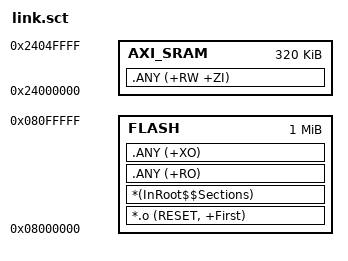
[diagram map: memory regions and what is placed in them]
; *********************************************************************************
; *** Scatter-Loading Description File generated by STM32CubeMX/LinkerGenerator ***
; *********************************************************************************;

ON_CHIP 0x08000000 0x00100000  {  ; load_region size_region
  FLASH 0x08000000 0x00100000  {  ; load address = excetion address
   *.o (RESET, +First)
   *(InRoot$$Sections)
   .ANY (+RO)
   .ANY (+XO)
  }
  AXI_SRAM 0x24000000 0x00050000  {  ; load address = excetion address
   .ANY (+RW +ZI)
  ;  *(.sram1)
  }
;***region***;
  ; ITCM 0x00000000 0x00010000  {  ; load address = excetion address
  ;  *(.itcm)
  ; }
  ; DTCM 0x20000000 0x00020000  {  ; load address = excetion address
  ;  *(.dtcm)
  ; }
  ; AHB_SRAM_D2 0x30000000 0x00008000  {  ; load address = excetion address
  ;  *(.sram2)
  ; }
  ; AHB_SRAM_D3 0x38000000 0x00004000  {  ; load address = excetion address
  ;  *(.sram3)
  ; }
  ; BACKUP_SRAM_D3 0x38800000 0x00001000  {  ; load address = excetion address
  ;  *(.bsram)
  ; }
;***endregion***;
}

/*-Start of  regions- Auto-generated By STM32CubeMX-*/
